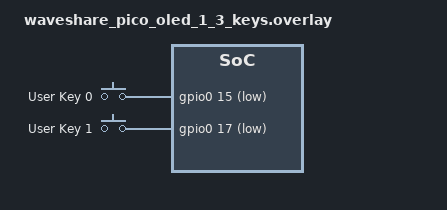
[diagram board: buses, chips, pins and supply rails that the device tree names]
/*
 * Copyright (c) 2023 TOKITA Hiroshi
 *
 * SPDX-License-Identifier: Apache-2.0
 */

#include <zephyr/dt-bindings/input/input-event-codes.h>

/ {
	buttons {
		compatible = "gpio-keys";
		key0: key0 {
			gpios = <&gpio0 15 (GPIO_PULL_UP | GPIO_ACTIVE_LOW)>;
			label = "User Key 0";
			zephyr,code = <INPUT_KEY_0>;
		};
		key1: key1 {
			gpios = <&gpio0 17 (GPIO_PULL_UP | GPIO_ACTIVE_LOW)>;
			label = "User Key 1";
			zephyr,code = <INPUT_KEY_1>;
		};
	};

	aliases {
		sw0 = &key0;
	};
};
